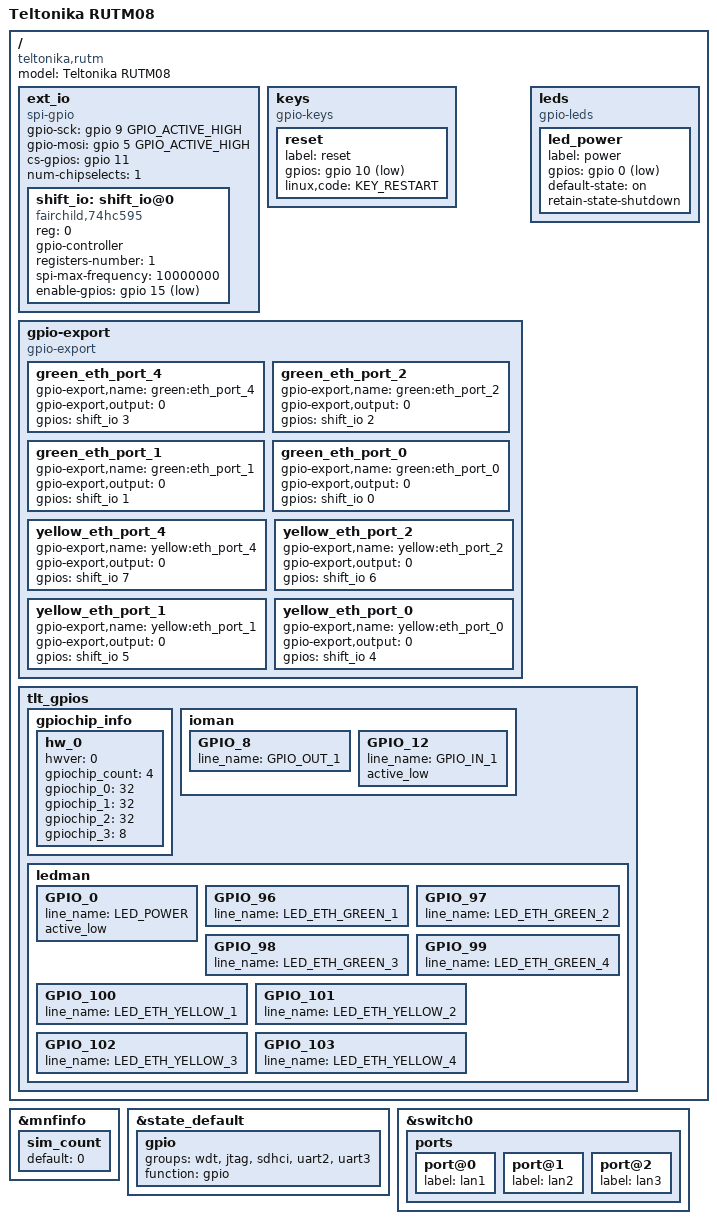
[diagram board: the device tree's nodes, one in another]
#include "mt7621-teltonika-rutm-common.dtsi"

/ {
	compatible = "teltonika,rutm", "mediatek,mt7621-soc";
	model = "Teltonika RUTM08";

	ext_io {
		compatible = "spi-gpio";
		#address-cells = <1>;
		#size-cells = <0>;

		gpio-sck = <&gpio 9 GPIO_ACTIVE_HIGH>;	// 74HC595 SRCLK (Serial Clock)
		gpio-mosi = <&gpio 5 GPIO_ACTIVE_HIGH>;	// 74HC595 SER (Serial)
		cs-gpios = <&gpio 11 GPIO_ACTIVE_HIGH>;	// 74HC595 RCLK (Register Clock)
		num-chipselects = <1>;

		shift_io: shift_io@0 {
			compatible = "fairchild,74hc595";
			reg = <0>;
			gpio-controller;
			#gpio-cells = <2>;
			registers-number = <1>;
			spi-max-frequency = <10000000>;
			enable-gpios = <&gpio 15 GPIO_ACTIVE_LOW>;
		};
	};

	keys {
		compatible = "gpio-keys";

		reset {
			label = "reset";
			gpios = <&gpio 10 GPIO_ACTIVE_LOW>;
			linux,code = <KEY_RESTART>;
		};
	};

	gpio-export {
		compatible = "gpio-export";
		#size-cells = <0>;

		green_eth_port_4 {
			gpio-export,name = "green:eth_port_4";
			gpio-export,output = <0>;
			gpios = <&shift_io 3 GPIO_ACTIVE_HIGH>;
		};

		green_eth_port_2 {
			gpio-export,name = "green:eth_port_2";
			gpio-export,output = <0>;
			gpios = <&shift_io 2 GPIO_ACTIVE_HIGH>;
		};

		green_eth_port_1 {
			gpio-export,name = "green:eth_port_1";
			gpio-export,output = <0>;
			gpios = <&shift_io 1 GPIO_ACTIVE_HIGH>;
		};

		green_eth_port_0 {
			gpio-export,name = "green:eth_port_0";
			gpio-export,output = <0>;
			gpios = <&shift_io 0 GPIO_ACTIVE_HIGH>;
		};

		yellow_eth_port_4 {
			gpio-export,name = "yellow:eth_port_4";
			gpio-export,output = <0>;
			gpios = <&shift_io 7 GPIO_ACTIVE_HIGH>;
		};

		yellow_eth_port_2 {
			gpio-export,name = "yellow:eth_port_2";
			gpio-export,output = <0>;
			gpios = <&shift_io 6 GPIO_ACTIVE_HIGH>;
		};

		yellow_eth_port_1 {
			gpio-export,name = "yellow:eth_port_1";
			gpio-export,output = <0>;
			gpios = <&shift_io 5 GPIO_ACTIVE_HIGH>;
		};

		yellow_eth_port_0 {
			gpio-export,name = "yellow:eth_port_0";
			gpio-export,output = <0>;
			gpios = <&shift_io 4 GPIO_ACTIVE_HIGH>;
		};

	};

	leds {
		compatible = "gpio-leds";

		led_power {
			label = "power";
			gpios = <&gpio 0 GPIO_ACTIVE_LOW>;
			default-state = "on";
			retain-state-shutdown;
		};
	};

	tlt_gpios { // Modify according to wiki page "DTS syntax with Libgpiod changes"
		gpiochip_info {
			hw_0 {
				hwver = <0>;
				gpiochip_count = <4>;

				gpiochip_0 = <32>; // Built-in
				gpiochip_1 = <32>; // Built-in
				gpiochip_2 = <32>; // Built-in
				gpiochip_3 = <8>;  // Shift Register
			};
		};

		ioman {
			GPIO_8 {
				line_name = "GPIO_OUT_1";
			};
			GPIO_12 {
				line_name = "GPIO_IN_1";
				active_low;
			};
		};

		ledman {
			GPIO_0 {
				line_name = "LED_POWER";
				active_low;
			};
			GPIO_96 {
				line_name = "LED_ETH_GREEN_1";
			};
			GPIO_97 {
				line_name = "LED_ETH_GREEN_2";
			};
			GPIO_98 {
				line_name = "LED_ETH_GREEN_3";
			};
			GPIO_99 {
				line_name = "LED_ETH_GREEN_4";
			};
			GPIO_100 {
				line_name = "LED_ETH_YELLOW_1";
			};
			GPIO_101 {
				line_name = "LED_ETH_YELLOW_2";
			};
			GPIO_102 {
				line_name = "LED_ETH_YELLOW_3";
			};
			GPIO_103 {
				line_name = "LED_ETH_YELLOW_4";
			};
		};
	};
};

&mnfinfo {
	/delete-node/ simpin1;
	/delete-node/ simpin2;

	sim_count {
		default =  "0";
	};
};

&state_default {
	gpio {
		groups = "wdt", "jtag", "sdhci", "uart2", "uart3";
		function = "gpio";
	};
};

&switch0 {
	ports {
		port@0 {
			status = "okay";
			label = "lan1";
		};

		port@1 {
			status = "okay";
			label = "lan2";
		};

		port@2 {
			status = "okay";
			label = "lan3";
		};
	};
};
